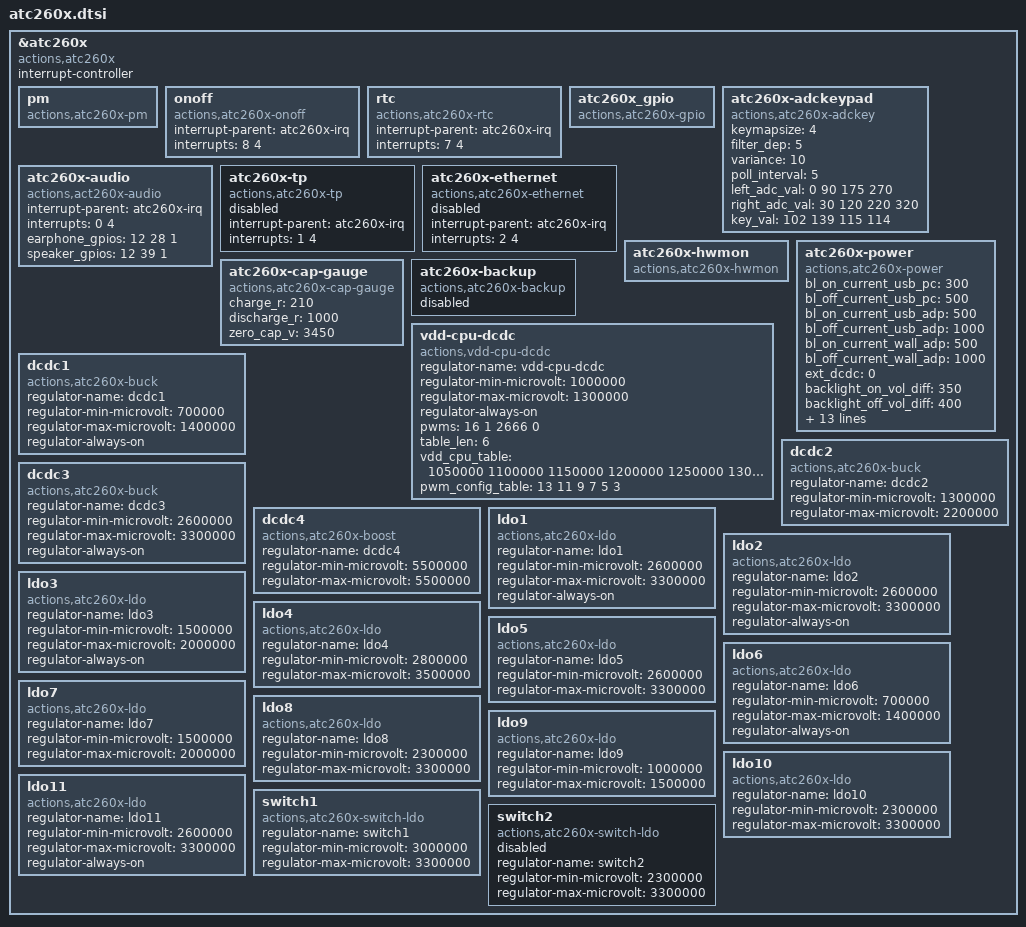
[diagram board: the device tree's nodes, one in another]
/*
 * Copyright (C) 2014
 * Author: B. Mouritsen <bnmguy@gmail.com>
 *
 * This program is free software; you can redistribute it and/or modify
 * it under the terms of the GNU General Public License as published by
 * the Free Software Foundation; either version 2 of the License, or
 * (at your option) any later version.
 *
 * This program is distributed in the hope that it will be useful,
 * but WITHOUT ANY WARRANTY; without even the implied warranty of
 * MERCHANTABILITY or FITNESS FOR A PARTICULAR PURPOSE.  See the
 * GNU General Public License for more details.
 */

/*
 * Power Management with Audio Codec Companion Chip
 */

&atc260x {
        compatible = "actions,atc260x";
        interrupt-controller;
        #interrupt-cells = <2>;

        pm {
                compatible = "actions,atc260x-pm";
        };

        onoff {
                compatible = "actions,atc260x-onoff";
                interrupt-parent = <&atc260x-irq>;
                interrupts = <8 4>;
        };

        rtc {
                compatible = "actions,atc260x-rtc";
                interrupt-parent = <&atc260x-irq>;
                interrupts = <7 4>;
        };

        atc260x_gpio {
                compatible = "actions,atc260x-gpio";
        };

        atc260x-adckeypad {
                keymapsize = <4>;
                filter_dep = <5>;
                variance = <10>;
                poll_interval = <5>;
                left_adc_val = <0 90 175 270>;
                right_adc_val = <30 120 220 320>;
                key_val = <102 139 115 114>;
                compatible = "actions,atc260x-adckey";
                status = "okay";
        };

        atc260x-audio {
                compatible = "actions,act260x-audio";
                interrupt-parent = <&atc260x-irq>;
                interrupts = <0 4>;
                status = "okay";
                earphone_gpios = <12 28 1>;
                speaker_gpios = <12 39 1>;
        };

        atc260x-tp {
                compatible = "actions,atc260x-tp";
                interrupt-parent = <&atc260x-irq>;
                interrupts = <1 4>;
                status = "disabled";
        };

        atc260x-ethernet {
                compatible = "actions,atc260x-ethernet";
                interrupt-parent = <&atc260x-irq>;
                interrupts = <2 4>;
                status = "disabled";
        };

        atc260x-hwmon {
                compatible = "actions,atc260x-hwmon";
        };

        atc260x-power {
                compatible = "actions,atc260x-power";
                bl_on_current_usb_pc = <300>;
                bl_off_current_usb_pc = <500>;
                bl_on_current_usb_adp = <500>;
                bl_off_current_usb_adp = <1000>;
                bl_on_current_wall_adp = <500>;
                bl_off_current_wall_adp = <1000>;
                ext_dcdc = <0>;
                backlight_on_vol_diff = <350>;
                backlight_off_vol_diff = <400>;
                pwms = <16 3 42 1>;
                pwm-names = "inter_charge_pwmctrl";
                ext_charger = <1>;
                ext_chg_ctrl_gpio = <12 115 0>;
                close_ext_chg_bl_on = <1>;
                charger_led_exist = <0>;
                charge_led_gpio = <12 15 1>;
                support_adaptor_type = <0>;
                charger_modify_wifi = <200>;
                charger_modify_camera = <200>;
                charger_modify_bklight_50 = <300>;
                charger_modify_bklight_75 = <100>;
                charger_modify_bklight_100 = <300>;
        };

        atc260x-cap-gauge {
                compatible = "actions,atc260x-cap-gauge";
                charge_r = <210>;
                discharge_r = <1000>;
                zero_cap_v = <3450>;
        };

        atc260x-backup {
                compatible = "actions,atc260x-backup";
                status = "disabled";
        };

        cpu-voltage: vdd-cpu-dcdc {
                compatible = "actions,vdd-cpu-dcdc";
                regulator-name = "vdd-cpu-dcdc";
        /*
         * If following CPU voltage limits end up
         * varying by device, then we will have to move
         * this to their board specific trees.
         */
                regulator-min-microvolt = <1000000>;
                regulator-max-microvolt = <1300000>;
                regulator-always-on;
                pwms = <16 1 2666 0>;
                table_len = <6>;
                vdd_cpu_table = <1050000 1100000 1150000 1200000 1250000 1300000>;
                pwm_config_table = <13 11 9 7 5 3>;
        };

        dcdc1 {
                compatible = "actions,atc260x-buck";
                regulator-name = "dcdc1";
                regulator-min-microvolt = <700000>;
                regulator-max-microvolt = <1400000>;
                regulator-always-on;
        };

        dcdc2 {
                compatible = "actions,atc260x-buck";
                regulator-name = "dcdc2";
                regulator-min-microvolt = <1300000>;
                regulator-max-microvolt = <2200000>;
        };

        dcdc3 {
                compatible = "actions,atc260x-buck";
                regulator-name = "dcdc3";
                regulator-min-microvolt = <2600000>;
                regulator-max-microvolt = <3300000>;
                regulator-always-on;
        };

        dcdc4 {
                compatible = "actions,atc260x-boost";
                regulator-name = "dcdc4";
                regulator-min-microvolt = <5500000>;
                regulator-max-microvolt = <5500000>;
        };

        ldo1 {
                compatible = "actions,atc260x-ldo";
                regulator-name = "ldo1";
                regulator-min-microvolt = <2600000>;
                regulator-max-microvolt = <3300000>;
                regulator-always-on;
        };

        ldo2 {
                compatible = "actions,atc260x-ldo";
                regulator-name = "ldo2";
                regulator-min-microvolt = <2600000>;
                regulator-max-microvolt = <3300000>;
                regulator-always-on;
        };

        ldo3 {
                compatible = "actions,atc260x-ldo";
                regulator-name = "ldo3";
                regulator-min-microvolt = <1500000>;
                regulator-max-microvolt = <2000000>;
                regulator-always-on;
        };

        ldo4 {
                compatible = "actions,atc260x-ldo";
                regulator-name = "ldo4";
                regulator-min-microvolt = <2800000>;
                regulator-max-microvolt = <3500000>;
        };

        ldo5 {
                compatible = "actions,atc260x-ldo";
                regulator-name = "ldo5";
                regulator-min-microvolt = <2600000>;
                regulator-max-microvolt = <3300000>;
        };

        ldo6 {
                compatible = "actions,atc260x-ldo";
                regulator-name = "ldo6";
                regulator-min-microvolt = <700000>;
                regulator-max-microvolt = <1400000>;
                regulator-always-on;
        };

        ldo7 {
                compatible = "actions,atc260x-ldo";
                regulator-name = "ldo7";
                regulator-min-microvolt = <1500000>;
                regulator-max-microvolt = <2000000>;
        };

        ldo8 {
                compatible = "actions,atc260x-ldo";
                regulator-name = "ldo8";
                regulator-min-microvolt = <2300000>;
                regulator-max-microvolt = <3300000>;
        };

        ldo9 {
                compatible = "actions,atc260x-ldo";
                regulator-name = "ldo9";
                regulator-min-microvolt = <1000000>;
                regulator-max-microvolt = <1500000>;
        };

        ldo10 {
                compatible = "actions,atc260x-ldo";
                regulator-name = "ldo10";
                regulator-min-microvolt = <2300000>;
                regulator-max-microvolt = <3300000>;
        };

        ldo11 {
                compatible = "actions,atc260x-ldo";
                regulator-name = "ldo11";
                regulator-min-microvolt = <2600000>;
                regulator-max-microvolt = <3300000>;
                regulator-always-on;
        };

        switch1 {
                compatible = "actions,atc260x-switch-ldo";
                regulator-name = "switch1";
                regulator-min-microvolt = <3000000>;
                regulator-max-microvolt = <3300000>;
        };

        switch2 {
                compatible = "actions,atc260x-switch-ldo";
                status = "disabled";
                regulator-name = "switch2";
                regulator-min-microvolt = <2300000>;
                regulator-max-microvolt = <3300000>;
        };
};
